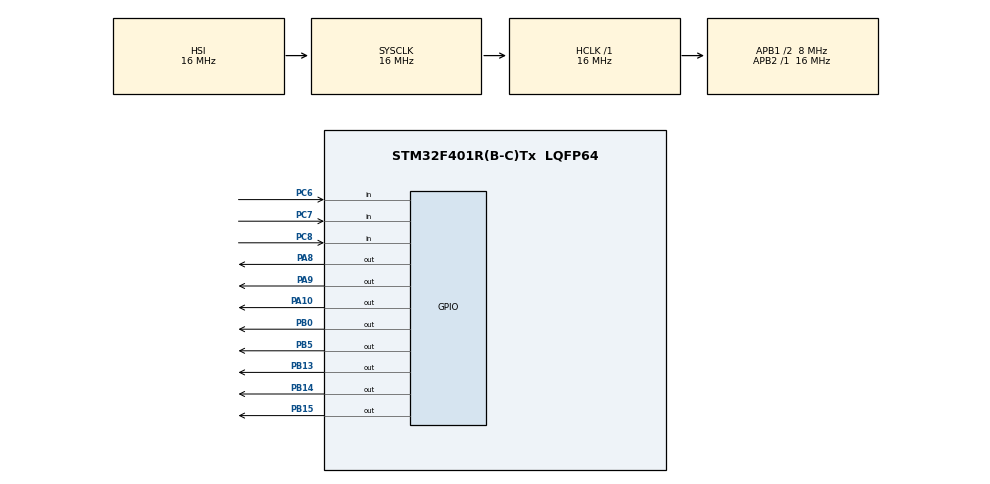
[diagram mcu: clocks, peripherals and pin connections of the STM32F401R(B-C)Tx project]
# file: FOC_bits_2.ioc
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Mcu.Family=STM32F4
Mcu.Name=STM32F401R(B-C)Tx
Mcu.Package=LQFP64
NVIC.PriorityGroup=NVIC_PRIORITYGROUP_4
PA10.GPIO_ModeDefaultOutputPP=GPIO_MODE_OUTPUT_PP
PA10.GPIO_PuPd=GPIO_PULLDOWN
PA10.GPIO_Speed=GPIO_SPEED_FREQ_VERY_HIGH
PA10.PinState=GPIO_PIN_RESET
PA10.Signal=GPIO_Output
PA13.Mode=Serial_Wire
PA13.Signal=SYS_JTMS-SWDIO
PA14.Mode=Serial_Wire
PA14.Signal=SYS_JTCK-SWCLK
PA8.GPIO_ModeDefaultOutputPP=GPIO_MODE_OUTPUT_PP
PA8.GPIO_PuPd=GPIO_PULLDOWN
PA8.GPIO_Speed=GPIO_SPEED_FREQ_VERY_HIGH
PA8.PinState=GPIO_PIN_RESET
PA8.Signal=GPIO_Output
PA9.GPIO_ModeDefaultOutputPP=GPIO_MODE_OUTPUT_PP
PA9.GPIO_PuPd=GPIO_PULLDOWN
PA9.GPIO_Speed=GPIO_SPEED_FREQ_VERY_HIGH
PA9.PinState=GPIO_PIN_RESET
PA9.Signal=GPIO_Output
PB0.GPIO_PuPd=GPIO_PULLDOWN
PB0.Signal=GPIO_Output
PB13.GPIO_ModeDefaultOutputPP=GPIO_MODE_OUTPUT_PP
PB13.GPIO_PuPd=GPIO_PULLDOWN
PB13.GPIO_Speed=GPIO_SPEED_FREQ_VERY_HIGH
PB13.PinState=GPIO_PIN_RESET
PB13.Signal=GPIO_Output
PB14.GPIO_ModeDefaultOutputPP=GPIO_MODE_OUTPUT_PP
PB14.GPIO_PuPd=GPIO_PULLDOWN
PB14.GPIO_Speed=GPIO_SPEED_FREQ_VERY_HIGH
PB14.PinState=GPIO_PIN_RESET
PB14.Signal=GPIO_Output
PB15.GPIO_ModeDefaultOutputPP=GPIO_MODE_OUTPUT_PP
PB15.GPIO_PuPd=GPIO_PULLDOWN
PB15.GPIO_Speed=GPIO_SPEED_FREQ_VERY_HIGH
PB15.PinState=GPIO_PIN_RESET
PB15.Signal=GPIO_Output
PB5.PinState=GPIO_PIN_SET
PB5.Signal=GPIO_Output
PC6.GPIO_PuPd=GPIO_PULLUP
PC6.Signal=GPIO_Input
PC7.GPIO_PuPd=GPIO_PULLUP
PC7.Signal=GPIO_Input
PC8.GPIO_PuPd=GPIO_PULLUP
PC8.Signal=GPIO_Input
PH0\ -\ OSC_IN.Mode=HSE-External-Oscillator
PH0\ -\ OSC_IN.Signal=RCC_OSC_IN
PH1\ -\ OSC_OUT.Mode=HSE-External-Oscillator
PH1\ -\ OSC_OUT.Signal=RCC_OSC_OUT
ProjectManager.HeapSize=0x200
ProjectManager.StackSize=0x400
ProjectManager.TargetToolchain=STM32CubeIDE
RCC.48MHZClocksFreq_Value=42000000
RCC.AHBFreq_Value=16000000
RCC.APB1CLKDivider=RCC_HCLK_DIV2
RCC.APB1Freq_Value=8000000
RCC.APB1TimFreq_Value=16000000
RCC.APB2Freq_Value=16000000
RCC.APB2TimFreq_Value=16000000
RCC.CortexFreq_Value=16000000
RCC.HCLKFreq_Value=16000000
RCC.HSE_VALUE=8000000
RCC.HSI_VALUE=16000000
RCC.LSE_VALUE=32768
RCC.PLLM=8
RCC.PLLN=84
RCC.SYSCLKFreq_VALUE=16000000
RCC.VCOOutputFreq_Value=168000000
TIM1.Period=999
TIM1.Prescaler=16
VP_TIM1_VS_ClockSourceINT.Mode=Internal
board=custom

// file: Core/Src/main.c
/* USER CODE BEGIN Header */
/**
  ******************************************************************************
  * @file           : main.c
  * @brief          : Main program body
  ******************************************************************************
  * @attention
  *
  * Copyright (c) 2024 STMicroelectronics.
  * All rights reserved.
  *
  * This software is licensed under terms that can be found in the LICENSE file
  * in the root directory of this software component.
  * If no LICENSE file comes with this software, it is provided AS-IS.
  *
  ******************************************************************************
  */
/* USER CODE END Header */
#include "main.h"

TIM_HandleTypeDef htim1;

void SystemClock_Config(void);
static void MX_GPIO_Init(void);
static void MX_TIM1_Init(void);

int main(void)
{

  /* MCU Configuration--------------------------------------------------------*/

  /* Reset of all peripherals, Initializes the Flash interface and the Systick. */
  HAL_Init();

  /* Configure the system clock */
  SystemClock_Config();

  /* Initialize all configured peripherals */
  MX_GPIO_Init();
  MX_TIM1_Init();

  /* Infinite loop */
  while (1)
  {

    /* USER CODE BEGIN 3 */
	  UpdatePhaseFromHall();
	  HAL_Delay(1); // Ajusta la velocidad del bucle según sea necesario
  }
  /* USER CODE END 3 */
}

void SystemClock_Config(void)
{
  RCC_OscInitTypeDef RCC_OscInitStruct = {0};
  RCC_ClkInitTypeDef RCC_ClkInitStruct = {0};

  /** Configure the main internal regulator output voltage
  */
  __HAL_RCC_PWR_CLK_ENABLE();
  __HAL_PWR_VOLTAGESCALING_CONFIG(PWR_REGULATOR_VOLTAGE_SCALE2);

  /** Initializes the RCC Oscillators according to the specified parameters
  * in the RCC_OscInitTypeDef structure.
  */
  RCC_OscInitStruct.OscillatorType = RCC_OSCILLATORTYPE_HSI;
  RCC_OscInitStruct.HSIState = RCC_HSI_ON;
  RCC_OscInitStruct.HSICalibrationValue = RCC_HSICALIBRATION_DEFAULT;
  RCC_OscInitStruct.PLL.PLLState = RCC_PLL_NONE;
  if (HAL_RCC_OscConfig(&RCC_OscInitStruct) != HAL_OK)
  {
    Error_Handler();
  }

  /** Initializes the CPU, AHB and APB buses clocks
  */
  RCC_ClkInitStruct.ClockType = RCC_CLOCKTYPE_HCLK|RCC_CLOCKTYPE_SYSCLK
                              |RCC_CLOCKTYPE_PCLK1|RCC_CLOCKTYPE_PCLK2;
  RCC_ClkInitStruct.SYSCLKSource = RCC_SYSCLKSOURCE_HSI;
  RCC_ClkInitStruct.AHBCLKDivider = RCC_SYSCLK_DIV1;
  RCC_ClkInitStruct.APB1CLKDivider = RCC_HCLK_DIV2;
  RCC_ClkInitStruct.APB2CLKDivider = RCC_HCLK_DIV1;

  if (HAL_RCC_ClockConfig(&RCC_ClkInitStruct, FLASH_LATENCY_0) != HAL_OK)
  {
    Error_Handler();
  }
}

static void MX_TIM1_Init(void)
{

  TIM_ClockConfigTypeDef sClockSourceConfig = {0};
  TIM_MasterConfigTypeDef sMasterConfig = {0};

  htim1.Instance = TIM1;
  htim1.Init.Prescaler = 16;
  htim1.Init.CounterMode = TIM_COUNTERMODE_UP;
  htim1.Init.Period = 999;
  htim1.Init.ClockDivision = TIM_CLOCKDIVISION_DIV1;
  htim1.Init.RepetitionCounter = 0;
  htim1.Init.AutoReloadPreload = TIM_AUTORELOAD_PRELOAD_DISABLE;
  if (HAL_TIM_Base_Init(&htim1) != HAL_OK)
  {
    Error_Handler();
  }
  sClockSourceConfig.ClockSource = TIM_CLOCKSOURCE_INTERNAL;
  if (HAL_TIM_ConfigClockSource(&htim1, &sClockSourceConfig) != HAL_OK)
  {
    Error_Handler();
  }
  sMasterConfig.MasterOutputTrigger = TIM_TRGO_RESET;
  sMasterConfig.MasterSlaveMode = TIM_MASTERSLAVEMODE_DISABLE;
  if (HAL_TIMEx_MasterConfigSynchronization(&htim1, &sMasterConfig) != HAL_OK)
  {
    Error_Handler();
  }

}

static void MX_GPIO_Init(void)
{
  GPIO_InitTypeDef GPIO_InitStruct = {0};

  /* GPIO Ports Clock Enable */
  __HAL_RCC_GPIOH_CLK_ENABLE();
  __HAL_RCC_GPIOB_CLK_ENABLE();
  __HAL_RCC_GPIOC_CLK_ENABLE();
  __HAL_RCC_GPIOA_CLK_ENABLE();

  /*Configure GPIO pin Output Level */
  HAL_GPIO_WritePin(GPIOB, GPIO_PIN_0|GPIO_PIN_13|GPIO_PIN_14|GPIO_PIN_15, GPIO_PIN_RESET);

  /*Configure GPIO pin Output Level */
  HAL_GPIO_WritePin(GPIOA, GPIO_PIN_8|GPIO_PIN_9|GPIO_PIN_10, GPIO_PIN_RESET);

  /*Configure GPIO pin Output Level */
  HAL_GPIO_WritePin(GPIOB, GPIO_PIN_5, GPIO_PIN_SET);

  /*Configure GPIO pin : PB0 */
  GPIO_InitStruct.Pin = GPIO_PIN_0;
  GPIO_InitStruct.Mode = GPIO_MODE_OUTPUT_PP;
  GPIO_InitStruct.Pull = GPIO_PULLDOWN;
  GPIO_InitStruct.Speed = GPIO_SPEED_FREQ_LOW;
  HAL_GPIO_Init(GPIOB, &GPIO_InitStruct);

  /*Configure GPIO pins : PB13 PB14 PB15 */
  GPIO_InitStruct.Pin = GPIO_PIN_13|GPIO_PIN_14|GPIO_PIN_15;
  GPIO_InitStruct.Mode = GPIO_MODE_OUTPUT_PP;
  GPIO_InitStruct.Pull = GPIO_PULLDOWN;
  GPIO_InitStruct.Speed = GPIO_SPEED_FREQ_VERY_HIGH;
  HAL_GPIO_Init(GPIOB, &GPIO_InitStruct);

  /*Configure GPIO pins : PC6 PC7 PC8 */
  GPIO_InitStruct.Pin = GPIO_PIN_6|GPIO_PIN_7|GPIO_PIN_8;
  GPIO_InitStruct.Mode = GPIO_MODE_INPUT;
  GPIO_InitStruct.Pull = GPIO_PULLUP;
  HAL_GPIO_Init(GPIOC, &GPIO_InitStruct);

  /*Configure GPIO pins : PA8 PA9 PA10 */
  GPIO_InitStruct.Pin = GPIO_PIN_8|GPIO_PIN_9|GPIO_PIN_10;
  GPIO_InitStruct.Mode = GPIO_MODE_OUTPUT_PP;
  GPIO_InitStruct.Pull = GPIO_PULLDOWN;
  GPIO_InitStruct.Speed = GPIO_SPEED_FREQ_VERY_HIGH;
  HAL_GPIO_Init(GPIOA, &GPIO_InitStruct);

  /*Configure GPIO pin : PB5 */
  GPIO_InitStruct.Pin = GPIO_PIN_5;
  GPIO_InitStruct.Mode = GPIO_MODE_OUTPUT_PP;
  GPIO_InitStruct.Pull = GPIO_NOPULL;
  GPIO_InitStruct.Speed = GPIO_SPEED_FREQ_LOW;
  HAL_GPIO_Init(GPIOB, &GPIO_InitStruct);

}

void Error_Handler(void)
{
  __disable_irq();
  while (1)
  {
  }
}
